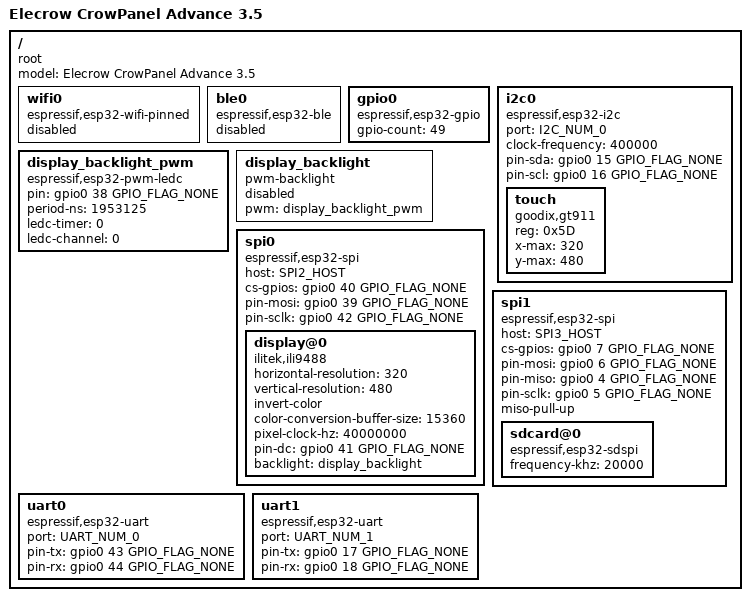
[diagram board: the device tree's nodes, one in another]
/dts-v1/;

#include <tactility/bindings/root.h>
#include <tactility/bindings/esp32_ble.h>
#include <tactility/bindings/esp32_wifi_pinned.h>
#include <tactility/bindings/esp32_gpio.h>
#include <tactility/bindings/esp32_i2c.h>
#include <tactility/bindings/esp32_spi.h>
#include <tactility/bindings/esp32_uart.h>
#include <tactility/bindings/esp32_sdspi.h>
#include <tactility/bindings/esp32_pwm_ledc.h>
#include <tactility/bindings/pwm_backlight.h>
#include <bindings/ili9488.h>
#include <bindings/gt911.h>

/ {
	compatible = "root";
	model = "Elecrow CrowPanel Advance 3.5";

	wifi0 {
		compatible = "espressif,esp32-wifi-pinned";
		status = "disabled";
	};

	ble0 {
		compatible = "espressif,esp32-ble";
		status = "disabled";
	};

	gpio0 {
		compatible = "espressif,esp32-gpio";
		gpio-count = <49>;
	};

	i2c0 {
		compatible = "espressif,esp32-i2c";
		port = <I2C_NUM_0>;
		clock-frequency = <400000>;
		pin-sda = <&gpio0 15 GPIO_FLAG_NONE>;
		pin-scl = <&gpio0 16 GPIO_FLAG_NONE>;

		touch {
			compatible = "goodix,gt911";
			reg = <0x5D>;
			x-max = <320>;
			y-max = <480>;
		};
	};

	display_backlight_pwm {
		compatible = "espressif,esp32-pwm-ledc";
		pin = <&gpio0 38 GPIO_FLAG_NONE>;
		period-ns = <1953125>;
		ledc-timer = <0>;
		ledc-channel = <0>;
	};

	display_backlight {
		compatible = "pwm-backlight";
		// Off by default so display power-on won't show the screen from before the last power loss.
		// The display backlight is turned on during the boot process.
		status = "disabled";
		pwm = <&display_backlight_pwm>;
	};

	spi0 {
		compatible = "espressif,esp32-spi";
		host = <SPI2_HOST>;
		cs-gpios = <&gpio0 40 GPIO_FLAG_NONE>;
		pin-mosi = <&gpio0 39 GPIO_FLAG_NONE>;
		pin-sclk = <&gpio0 42 GPIO_FLAG_NONE>;

		display@0 {
			compatible = "ilitek,ili9488";
			horizontal-resolution = <320>;
			vertical-resolution = <480>;
			invert-color;
			color-conversion-buffer-size = <15360>;
			pixel-clock-hz = <40000000>;
			pin-dc = <&gpio0 41 GPIO_FLAG_NONE>;
			backlight = <&display_backlight>;
		};
	};

	spi1 {
		compatible = "espressif,esp32-spi";
		host = <SPI3_HOST>;
		cs-gpios = <&gpio0 7 GPIO_FLAG_NONE>;
		pin-mosi = <&gpio0 6 GPIO_FLAG_NONE>;
		pin-miso = <&gpio0 4 GPIO_FLAG_NONE>;
		pin-sclk = <&gpio0 5 GPIO_FLAG_NONE>;
		miso-pull-up;

		sdcard@0 {
			compatible = "espressif,esp32-sdspi";
			frequency-khz = <20000>;
		};
	};

	uart0 {
		compatible = "espressif,esp32-uart";
		port = <UART_NUM_0>;
		pin-tx = <&gpio0 43 GPIO_FLAG_NONE>;
		pin-rx = <&gpio0 44 GPIO_FLAG_NONE>;
	};

	uart1 {
		compatible = "espressif,esp32-uart";
		port = <UART_NUM_1>;
		pin-tx = <&gpio0 17 GPIO_FLAG_NONE>;
		pin-rx = <&gpio0 18 GPIO_FLAG_NONE>;
	};
};
